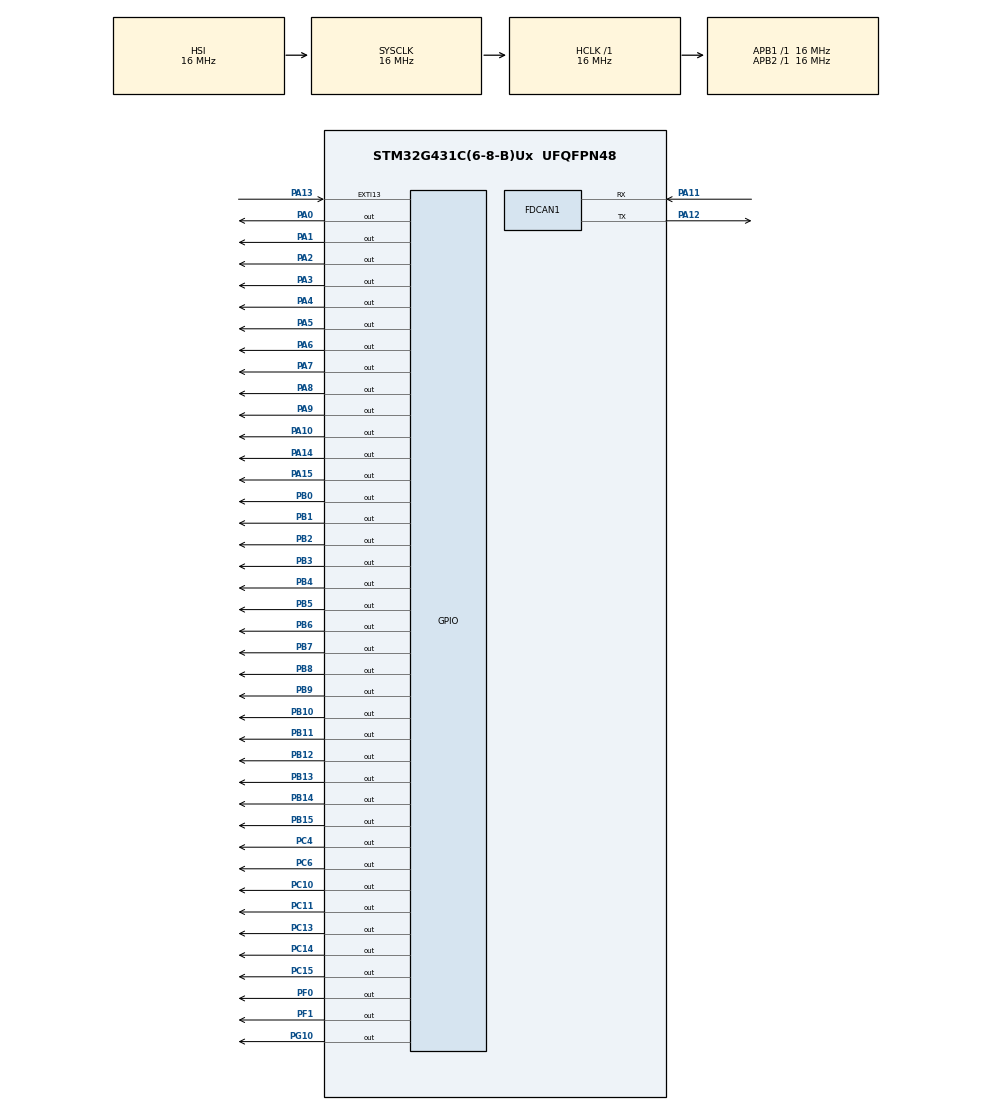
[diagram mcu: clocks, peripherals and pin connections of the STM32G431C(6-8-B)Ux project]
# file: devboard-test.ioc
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FDCAN1.CalculateBaudRateNominal=200000
FDCAN1.CalculateTimeBitNominal=5000
FDCAN1.CalculateTimeQuantumNominal=1000.0
Mcu.Family=STM32G4
Mcu.Name=STM32G431C(6-8-B)Ux
Mcu.Package=UFQFPN48
NVIC.PriorityGroup=NVIC_PRIORITYGROUP_4
PA0.Signal=GPIO_Output
PA1.Signal=GPIO_Output
PA10.Signal=GPIO_Output
PA11.Mode=FDCAN_Activate
PA11.Signal=FDCAN1_RX
PA12.Mode=FDCAN_Activate
PA12.Signal=FDCAN1_TX
PA13.Signal=GPXTI13
PA14.Signal=GPIO_Output
PA15.Signal=GPIO_Output
PA2.Signal=GPIO_Output
PA3.Signal=GPIO_Output
PA4.Signal=GPIO_Output
PA5.Signal=GPIO_Output
PA6.Signal=GPIO_Output
PA7.Signal=GPIO_Output
PA8.Signal=GPIO_Output
PA9.Signal=GPIO_Output
PB0.Signal=GPIO_Output
PB1.Signal=GPIO_Output
PB10.Signal=GPIO_Output
PB11.Signal=GPIO_Output
PB12.Signal=GPIO_Output
PB13.Signal=GPIO_Output
PB14.Signal=GPIO_Output
PB15.Signal=GPIO_Output
PB2.Signal=GPIO_Output
PB3.Signal=GPIO_Output
PB4.Signal=GPIO_Output
PB5.Signal=GPIO_Output
PB6.Signal=GPIO_Output
PB7.Signal=GPIO_Output
PB8-BOOT0.Signal=GPIO_Output
PB9.Signal=GPIO_Output
PC10.Signal=GPIO_Output
PC11.Signal=GPIO_Output
PC13.Signal=GPIO_Output
PC14-OSC32_IN.Signal=GPIO_Output
PC15-OSC32_OUT.Signal=GPIO_Output
PC4.Signal=GPIO_Output
PC6.Signal=GPIO_Output
PF0-OSC_IN.Signal=GPIO_Output
PF1-OSC_OUT.Signal=GPIO_Output
PG10-NRST.Signal=GPIO_Output
ProjectManager.HeapSize=0x200
ProjectManager.StackSize=0x400
ProjectManager.TargetToolchain=STM32CubeIDE
RCC.AHBFreq_Value=16000000
RCC.APB1Freq_Value=16000000
RCC.APB1TimFreq_Value=16000000
RCC.APB2Freq_Value=16000000
RCC.APB2TimFreq_Value=16000000
RCC.CortexFreq_Value=16000000
RCC.EXTERNAL_CLOCK_VALUE=12288000
RCC.HCLKFreq_Value=16000000
RCC.HSE_VALUE=8000000
RCC.HSI48_VALUE=48000000
RCC.HSI_VALUE=16000000
RCC.LSE_VALUE=32768
RCC.SYSCLKFreq_VALUE=16000000
RCC.USBFreq_Value=64000000
RCC.VCOOutputFreq_Value=128000000
board=custom

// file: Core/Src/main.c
/* USER CODE BEGIN Header */
/**
  ******************************************************************************
  * @file           : main.c
  * @brief          : Main program body
  ******************************************************************************
  * @attention
  *
  * Copyright (c) 2023 STMicroelectronics.
  * All rights reserved.
  *
  * This software is licensed under terms that can be found in the LICENSE file
  * in the root directory of this software component.
  * If no LICENSE file comes with this software, it is provided AS-IS.
  *
  ******************************************************************************
  */
/* USER CODE END Header */
#include "main.h"

FDCAN_HandleTypeDef hfdcan1;

void SystemClock_Config(void);
static void MX_GPIO_Init(void);
static void MX_FDCAN1_Init(void);

int main(void)
{

  /* MCU Configuration--------------------------------------------------------*/

  /* Reset of all peripherals, Initializes the Flash interface and the Systick. */
  HAL_Init();

  /* Configure the system clock */
  SystemClock_Config();

  /* Initialize all configured peripherals */
  MX_GPIO_Init();
  MX_FDCAN1_Init();

  /* Infinite loop */
  while (1)
  {

    /* USER CODE BEGIN 3 */
	  for (uint16_t i = 0; i < 16; ++i) {
		  HAL_GPIO_TogglePin(GPIOA, i);
		  HAL_Delay(100);
		  HAL_GPIO_TogglePin(GPIOB, i);
		  HAL_Delay(100);
		  HAL_GPIO_TogglePin(GPIOC, i);
		  HAL_Delay(100);
		  HAL_GPIO_TogglePin(GPIOD, i);
		  HAL_Delay(100);
		  HAL_GPIO_TogglePin(GPIOF, i);
		  HAL_Delay(100);
		  HAL_GPIO_TogglePin(GPIOG, i);
		  HAL_Delay(100);
	  }

	  HAL_Delay(300);

	  // send CAN message

  }
  /* USER CODE END 3 */
}

void SystemClock_Config(void)
{
  RCC_OscInitTypeDef RCC_OscInitStruct = {0};
  RCC_ClkInitTypeDef RCC_ClkInitStruct = {0};

  /** Configure the main internal regulator output voltage
  */
  HAL_PWREx_ControlVoltageScaling(PWR_REGULATOR_VOLTAGE_SCALE1);

  /** Initializes the RCC Oscillators according to the specified parameters
  * in the RCC_OscInitTypeDef structure.
  */
  RCC_OscInitStruct.OscillatorType = RCC_OSCILLATORTYPE_HSI;
  RCC_OscInitStruct.HSIState = RCC_HSI_ON;
  RCC_OscInitStruct.HSICalibrationValue = RCC_HSICALIBRATION_DEFAULT;
  RCC_OscInitStruct.PLL.PLLState = RCC_PLL_NONE;
  if (HAL_RCC_OscConfig(&RCC_OscInitStruct) != HAL_OK)
  {
    Error_Handler();
  }

  /** Initializes the CPU, AHB and APB buses clocks
  */
  RCC_ClkInitStruct.ClockType = RCC_CLOCKTYPE_HCLK|RCC_CLOCKTYPE_SYSCLK
                              |RCC_CLOCKTYPE_PCLK1|RCC_CLOCKTYPE_PCLK2;
  RCC_ClkInitStruct.SYSCLKSource = RCC_SYSCLKSOURCE_HSI;
  RCC_ClkInitStruct.AHBCLKDivider = RCC_SYSCLK_DIV1;
  RCC_ClkInitStruct.APB1CLKDivider = RCC_HCLK_DIV1;
  RCC_ClkInitStruct.APB2CLKDivider = RCC_HCLK_DIV1;

  if (HAL_RCC_ClockConfig(&RCC_ClkInitStruct, FLASH_LATENCY_0) != HAL_OK)
  {
    Error_Handler();
  }
}

static void MX_FDCAN1_Init(void)
{

  hfdcan1.Instance = FDCAN1;
  hfdcan1.Init.ClockDivider = FDCAN_CLOCK_DIV1;
  hfdcan1.Init.FrameFormat = FDCAN_FRAME_CLASSIC;
  hfdcan1.Init.Mode = FDCAN_MODE_NORMAL;
  hfdcan1.Init.AutoRetransmission = DISABLE;
  hfdcan1.Init.TransmitPause = DISABLE;
  hfdcan1.Init.ProtocolException = DISABLE;
  hfdcan1.Init.NominalPrescaler = 16;
  hfdcan1.Init.NominalSyncJumpWidth = 1;
  hfdcan1.Init.NominalTimeSeg1 = 2;
  hfdcan1.Init.NominalTimeSeg2 = 2;
  hfdcan1.Init.DataPrescaler = 1;
  hfdcan1.Init.DataSyncJumpWidth = 1;
  hfdcan1.Init.DataTimeSeg1 = 1;
  hfdcan1.Init.DataTimeSeg2 = 1;
  hfdcan1.Init.StdFiltersNbr = 0;
  hfdcan1.Init.ExtFiltersNbr = 0;
  hfdcan1.Init.TxFifoQueueMode = FDCAN_TX_FIFO_OPERATION;
  if (HAL_FDCAN_Init(&hfdcan1) != HAL_OK)
  {
    Error_Handler();
  }

}

static void MX_GPIO_Init(void)
{
  GPIO_InitTypeDef GPIO_InitStruct = {0};

  /* GPIO Ports Clock Enable */
  __HAL_RCC_GPIOC_CLK_ENABLE();
  __HAL_RCC_GPIOF_CLK_ENABLE();
  __HAL_RCC_GPIOG_CLK_ENABLE();
  __HAL_RCC_GPIOA_CLK_ENABLE();
  __HAL_RCC_GPIOB_CLK_ENABLE();

  /*Configure GPIO pin Output Level */
  HAL_GPIO_WritePin(GPIOC, GPIO_PIN_13|GPIO_PIN_14|GPIO_PIN_15|GPIO_PIN_4
                          |GPIO_PIN_6|GPIO_PIN_10|GPIO_PIN_11, GPIO_PIN_RESET);

  /*Configure GPIO pin Output Level */
  HAL_GPIO_WritePin(GPIOF, GPIO_PIN_0|GPIO_PIN_1, GPIO_PIN_RESET);

  /*Configure GPIO pin Output Level */
  HAL_GPIO_WritePin(GPIOG, GPIO_PIN_10, GPIO_PIN_RESET);

  /*Configure GPIO pin Output Level */
  HAL_GPIO_WritePin(GPIOA, GPIO_PIN_0|GPIO_PIN_1|GPIO_PIN_2|GPIO_PIN_3
                          |GPIO_PIN_4|GPIO_PIN_5|GPIO_PIN_6|GPIO_PIN_7
                          |GPIO_PIN_8|GPIO_PIN_9|GPIO_PIN_10|GPIO_PIN_14
                          |GPIO_PIN_15, GPIO_PIN_RESET);

  /*Configure GPIO pin Output Level */
  HAL_GPIO_WritePin(GPIOB, GPIO_PIN_0|GPIO_PIN_1|GPIO_PIN_2|GPIO_PIN_10
                          |GPIO_PIN_11|GPIO_PIN_12|GPIO_PIN_13|GPIO_PIN_14
                          |GPIO_PIN_15|GPIO_PIN_3|GPIO_PIN_4|GPIO_PIN_5
                          |GPIO_PIN_6|GPIO_PIN_7|GPIO_PIN_8|GPIO_PIN_9, GPIO_PIN_RESET);

  /*Configure GPIO pins : PC13 PC14 PC15 PC4
                           PC6 PC10 PC11 */
  GPIO_InitStruct.Pin = GPIO_PIN_13|GPIO_PIN_14|GPIO_PIN_15|GPIO_PIN_4
                          |GPIO_PIN_6|GPIO_PIN_10|GPIO_PIN_11;
  GPIO_InitStruct.Mode = GPIO_MODE_OUTPUT_PP;
  GPIO_InitStruct.Pull = GPIO_NOPULL;
  GPIO_InitStruct.Speed = GPIO_SPEED_FREQ_LOW;
  HAL_GPIO_Init(GPIOC, &GPIO_InitStruct);

  /*Configure GPIO pins : PF0 PF1 */
  GPIO_InitStruct.Pin = GPIO_PIN_0|GPIO_PIN_1;
  GPIO_InitStruct.Mode = GPIO_MODE_OUTPUT_PP;
  GPIO_InitStruct.Pull = GPIO_NOPULL;
  GPIO_InitStruct.Speed = GPIO_SPEED_FREQ_LOW;
  HAL_GPIO_Init(GPIOF, &GPIO_InitStruct);

  /*Configure GPIO pin : PG10 */
  GPIO_InitStruct.Pin = GPIO_PIN_10;
  GPIO_InitStruct.Mode = GPIO_MODE_OUTPUT_PP;
  GPIO_InitStruct.Pull = GPIO_NOPULL;
  GPIO_InitStruct.Speed = GPIO_SPEED_FREQ_LOW;
  HAL_GPIO_Init(GPIOG, &GPIO_InitStruct);

  /*Configure GPIO pins : PA0 PA1 PA2 PA3
                           PA4 PA5 PA6 PA7
                           PA8 PA9 PA10 PA14
                           PA15 */
  GPIO_InitStruct.Pin = GPIO_PIN_0|GPIO_PIN_1|GPIO_PIN_2|GPIO_PIN_3
                          |GPIO_PIN_4|GPIO_PIN_5|GPIO_PIN_6|GPIO_PIN_7
                          |GPIO_PIN_8|GPIO_PIN_9|GPIO_PIN_10|GPIO_PIN_14
                          |GPIO_PIN_15;
  GPIO_InitStruct.Mode = GPIO_MODE_OUTPUT_PP;
  GPIO_InitStruct.Pull = GPIO_NOPULL;
  GPIO_InitStruct.Speed = GPIO_SPEED_FREQ_LOW;
  HAL_GPIO_Init(GPIOA, &GPIO_InitStruct);

  /*Configure GPIO pins : PB0 PB1 PB2 PB10
                           PB11 PB12 PB13 PB14
                           PB15 PB3 PB4 PB5
                           PB6 PB7 PB8 PB9 */
  GPIO_InitStruct.Pin = GPIO_PIN_0|GPIO_PIN_1|GPIO_PIN_2|GPIO_PIN_10
                          |GPIO_PIN_11|GPIO_PIN_12|GPIO_PIN_13|GPIO_PIN_14
                          |GPIO_PIN_15|GPIO_PIN_3|GPIO_PIN_4|GPIO_PIN_5
                          |GPIO_PIN_6|GPIO_PIN_7|GPIO_PIN_8|GPIO_PIN_9;
  GPIO_InitStruct.Mode = GPIO_MODE_OUTPUT_PP;
  GPIO_InitStruct.Pull = GPIO_NOPULL;
  GPIO_InitStruct.Speed = GPIO_SPEED_FREQ_LOW;
  HAL_GPIO_Init(GPIOB, &GPIO_InitStruct);

  /*Configure GPIO pin : PA13 */
  GPIO_InitStruct.Pin = GPIO_PIN_13;
  GPIO_InitStruct.Mode = GPIO_MODE_IT_RISING;
  GPIO_InitStruct.Pull = GPIO_NOPULL;
  HAL_GPIO_Init(GPIOA, &GPIO_InitStruct);

}

void Error_Handler(void)
{
  __disable_irq();
  while (1)
  {
  }
}
